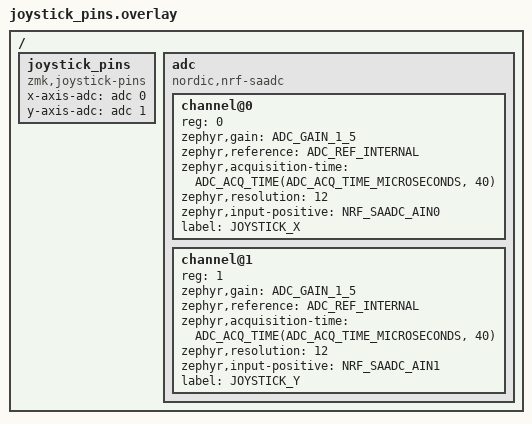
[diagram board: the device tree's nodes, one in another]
/ {
    joystick_pins: joystick_pins {
        compatible = "zmk,joystick-pins";
        
        x-axis-adc = <&adc 0>;  // AIN0 (P0.02)
        y-axis-adc = <&adc 1>;  // AIN1 (P0.03)
        
        status = "okay";
    };
    
    adc {
        compatible = "nordic,nrf-saadc";
        status = "okay";
        #io-channel-cells = <1>;
        
        channel@0 {
            reg = <0>;
            zephyr,gain = "ADC_GAIN_1_5";
            zephyr,reference = "ADC_REF_INTERNAL";
            zephyr,acquisition-time = <ADC_ACQ_TIME(ADC_ACQ_TIME_MICROSECONDS, 40)>;
            zephyr,resolution = <12>;
            zephyr,input-positive = <NRF_SAADC_AIN0>;
            label = "JOYSTICK_X";
        };
        
        channel@1 {
            reg = <1>;
            zephyr,gain = "ADC_GAIN_1_5";
            zephyr,reference = "ADC_REF_INTERNAL";
            zephyr,acquisition-time = <ADC_ACQ_TIME(ADC_ACQ_TIME_MICROSECONDS, 40)>;
            zephyr,resolution = <12>;
            zephyr,input-positive = <NRF_SAADC_AIN1>;
            label = "JOYSTICK_Y";
        };
    };
};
